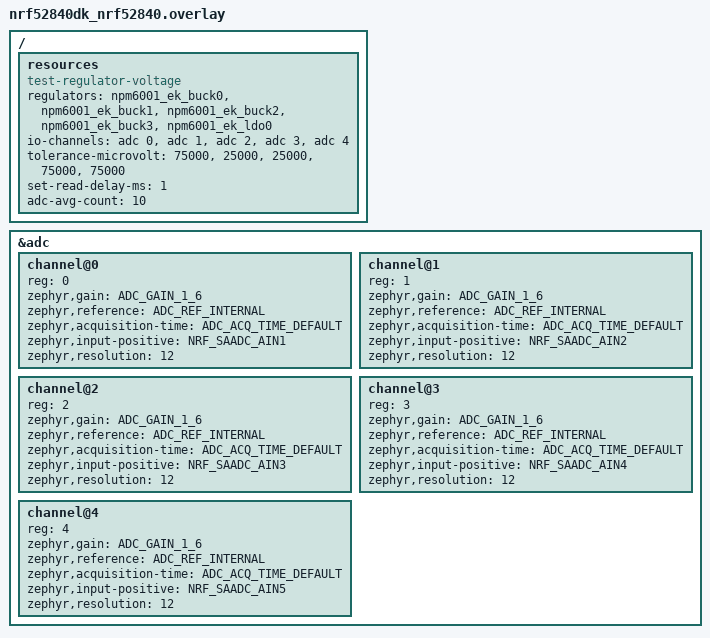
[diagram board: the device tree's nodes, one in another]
/*
 * Copyright (c) 2022 Nordic Semiconductor ASA
 * SPDX-License-Identifier: Apache-2.0
 */

/ {
	/* NOTE: LDO0 change rate is low, so test may fail if its previous
	 * voltage was much higher than 1.8V, e.g. 3.3V. Wait a few seconds and
	 * re-run the test.
	 */
	resources: resources {
		compatible = "test-regulator-voltage";
		regulators = <&npm6001_ek_buck0 &npm6001_ek_buck1
			      &npm6001_ek_buck2 &npm6001_ek_buck3
			      &npm6001_ek_ldo0>;
		io-channels = <&adc 0>, <&adc 1>, <&adc 2>, <&adc 3>, <&adc 4>;
		tolerance-microvolt = <75000>, <25000>, <25000>, <75000>,
				      <75000>;
		set-read-delay-ms = <1>;
		adc-avg-count = <10>;
	};
};

&adc {
	#address-cells = <1>;
	#size-cells = <0>;

	channel@0 {
		reg = <0>;
		zephyr,gain = "ADC_GAIN_1_6";
		zephyr,reference = "ADC_REF_INTERNAL";
		zephyr,acquisition-time = <ADC_ACQ_TIME_DEFAULT>;
		zephyr,input-positive = <NRF_SAADC_AIN1>; /* P0.03 */
		zephyr,resolution = <12>;
	};

	channel@1 {
		reg = <1>;
		zephyr,gain = "ADC_GAIN_1_6";
		zephyr,reference = "ADC_REF_INTERNAL";
		zephyr,acquisition-time = <ADC_ACQ_TIME_DEFAULT>;
		zephyr,input-positive = <NRF_SAADC_AIN2>; /* P0.04 */
		zephyr,resolution = <12>;
	};

	channel@2 {
		reg = <2>;
		zephyr,gain = "ADC_GAIN_1_6";
		zephyr,reference = "ADC_REF_INTERNAL";
		zephyr,acquisition-time = <ADC_ACQ_TIME_DEFAULT>;
		zephyr,input-positive = <NRF_SAADC_AIN3>; /* P0.05 */
		zephyr,resolution = <12>;
	};

	channel@3 {
		reg = <3>;
		zephyr,gain = "ADC_GAIN_1_6";
		zephyr,reference = "ADC_REF_INTERNAL";
		zephyr,acquisition-time = <ADC_ACQ_TIME_DEFAULT>;
		zephyr,input-positive = <NRF_SAADC_AIN4>; /* P0.28 */
		zephyr,resolution = <12>;
	};

	channel@4 {
		reg = <4>;
		zephyr,gain = "ADC_GAIN_1_6";
		zephyr,reference = "ADC_REF_INTERNAL";
		zephyr,acquisition-time = <ADC_ACQ_TIME_DEFAULT>;
		zephyr,input-positive = <NRF_SAADC_AIN5>; /* P0.29 */
		zephyr,resolution = <12>;
	};
};
